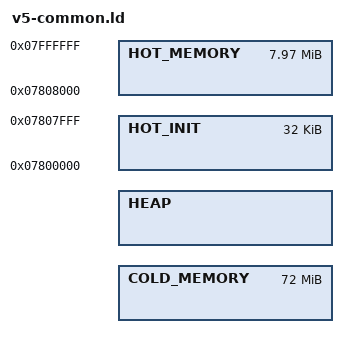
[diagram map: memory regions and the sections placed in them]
_HEAP_SIZE = DEFINED(_HEAP_SIZE) ? _HEAP_SIZE : 0x02E00000;  /* ~48 MB */

MEMORY
{
   /* user code  72M */
   COLD_MEMORY : ORIGIN = 0x0380 0000, LENGTH = 0x04800000 /* Just under 19 MB */
   HEAP : ORIGIN = 0x04A0 0000, LENGTH = _HEAP_SIZE
   HOT_INIT : ORIGIN = 0x007800000, LENGTH = 0x00008000  /* 32 KiB */
   HOT_MEMORY : ORIGIN = 0x07808000, LENGTH = 0x007F8000  /* Just over 8 MB */
}
